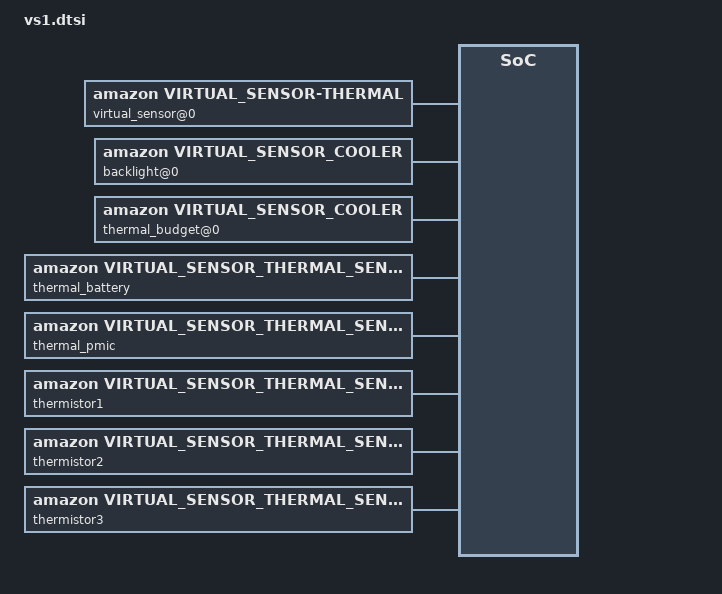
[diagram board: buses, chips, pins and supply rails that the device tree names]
/*
 * Copyright (C) 2019-2020 Amazon Technologies Inc. All rights reserved.
 *
 * This program is free software; you can redistribute it and/or modify
 * it under the terms of the GNU General Public License version 2 as
 * published by the Free Software Foundation.
 *
 * This program is distributed in the hope that it will be useful,
 * MERCHANTABILITY or FITNESS FOR A PARTICULAR PURPOSE.  See the
 * GNU General Public License for more details.
 */

/*
 * Virtual sensor
 * select_device: Decide to register which thermal_zone device
 * 0: register to thermal_zone16, 1: register to thermal_zone17
 */
virtual_sensor@0 {
	compatible = "amazon,virtual_sensor-thermal";
	dev_id = <0>;
	num_trips = <9>;
	mode = <0>;
	polling_delay = <3000>;
	governor_name = "virtual_sensor";
	num_tbps = <3>;
	temp = <44500 45000 47000 49000 50000 52000 54000 55000 56000 56000 56000 56000>;
	type = <0 0 0 0 0 0 0 0 3 3 3 3>;
	hyst = <0 0 0 0 0 0 0 3000 0 0 0 0>;
	num_cdevs = <2>;
	cdev_names = "thermal_budget0","lcd-backlight0";
};

/* Backlight Cooler */
backlight@0 {
	compatible = "amazon,virtual_sensor_cooler";
	type = "lcd-backlight0";
	state = <0>;
	max_state = <12>;
	level = <255>;
	max_level = <255>;
	thermal_cooler_id = <1>;
	levels = <255 255 255 255 255 255 175 175 175 175 175 175>;
};

/* Thermal_budget Cooler */
thermal_budget@0 {
	compatible = "amazon,virtual_sensor_cooler";
	type = "thermal_budget0";
	state = <0>;
	max_state = <12>;
	level = <4600>;
	max_level = <4600>;
	thermal_cooler_id = <2>;
	levels = <1921 1751 1669 1669 1562 1461 1358 1000 1000 1000 1000 1000>;
};

vs1_wire: vs1_wire {
	compatible = "amazon,vs1_wire", "simple-bus";
	status = "okay";
	/*Virtual sensor battery*/
	thermal_battery {
		compatible = "amazon,virtual_sensor_thermal_sensor";
		thermal_sensor,offset = <6130>;
		thermal_sensor,offset_invert = <1>;
		thermal_sensor,alpha = <1000>;
		thermal_sensor,weight = <515>;
		thermal_sensor,weight_invert = <0>;
		thermal_sensor_id = <1>;
		aux_channel_num = <0>;
		select_device = <0>;
	};

	/*Virtual sensor pmic*/
	thermal_pmic {
		compatible = "amazon,virtual_sensor_thermal_sensor";
		thermal_sensor,offset = <11200>;
		thermal_sensor,offset_invert = <1>;
		thermal_sensor,alpha = <1000>;
		thermal_sensor,weight = <262>;
		thermal_sensor,weight_invert = <0>;
		thermal_sensor_id = <3>;
		aux_channel_num = <0>;
		select_device = <0>;
	};

	/* Virtual sensor thermistor */
	thermistor1 {
		compatible = "amazon,virtual_sensor_thermal_sensor";
		thermal_sensor,offset = <33500>;
		thermal_sensor,offset_invert = <0>;
		thermal_sensor,alpha = <1000>;
		thermal_sensor,weight = <102>;
		thermal_sensor,weight_invert = <0>;
		thermal_sensor_id = <5>;
		aux_channel_num = <1>;
		select_device = <0>;
	};

	thermistor2 {
		compatible = "amazon,virtual_sensor_thermal_sensor";
		thermal_sensor,offset = <51700>;
		thermal_sensor,offset_invert = <0>;
		thermal_sensor,alpha = <1>;
		thermal_sensor,weight = <0>;
		thermal_sensor,weight_invert = <0>;
		thermal_sensor_id = <5>;
		aux_channel_num = <2>;
		select_device = <0>;
	};

	thermistor3 {
		compatible = "amazon,virtual_sensor_thermal_sensor";
		thermal_sensor,offset = <46700>;
		thermal_sensor,offset_invert = <0>;
		thermal_sensor,alpha = <147>;
		thermal_sensor,weight = <0>;
		thermal_sensor,weight_invert = <0>;
		thermal_sensor_id = <5>;
		aux_channel_num = <3>;
		select_device = <0>;
	};
};

vs1_wpc: vs1_wpc {
	compatible = "amazon,vs1_wpc", "simple-bus";
	status = "disabled";
	/*Virtual sensor battery*/
	thermal_battery {
		compatible = "amazon,virtual_sensor_thermal_sensor";
		thermal_sensor,offset = <35000>;
		thermal_sensor,offset_invert = <0>;
		thermal_sensor,alpha = <738>;
		thermal_sensor,weight = <192>;
		thermal_sensor,weight_invert = <0>;
		thermal_sensor_id = <1>;
		aux_channel_num = <0>;
		select_device = <0>;
	};

	/*Virtual sensor pmic*/
	thermal_pmic {
		compatible = "amazon,virtual_sensor_thermal_sensor";
		thermal_sensor,offset = <56500>;
		thermal_sensor,offset_invert = <0>;
		thermal_sensor,alpha = <417>;
		thermal_sensor,weight = <0>;
		thermal_sensor,weight_invert = <0>;
		thermal_sensor_id = <3>;
		aux_channel_num = <0>;
		select_device = <0>;
	};

	/* Virtual sensor thermistor */
	thermistor1 {
		compatible = "amazon,virtual_sensor_thermal_sensor";
		thermal_sensor,offset = <6420>;
		thermal_sensor,offset_invert = <0>;
		thermal_sensor,alpha = <1000>;
		thermal_sensor,weight = <943>;
		thermal_sensor,weight_invert = <0>;
		thermal_sensor_id = <5>;
		aux_channel_num = <1>;
		select_device = <0>;
	};

	thermistor2 {
		compatible = "amazon,virtual_sensor_thermal_sensor";
		thermal_sensor,offset = <53900>;
		thermal_sensor,offset_invert = <0>;
		thermal_sensor,alpha = <1>;
		thermal_sensor,weight = <0>;
		thermal_sensor,weight_invert = <0>;
		thermal_sensor_id = <5>;
		aux_channel_num = <2>;
		select_device = <0>;
	};

	thermistor3 {
		compatible = "amazon,virtual_sensor_thermal_sensor";
		thermal_sensor,offset = <61800>;
		thermal_sensor,offset_invert = <0>;
		thermal_sensor,alpha = <4>;
		thermal_sensor,weight = <276>;
		thermal_sensor,weight_invert = <1>;
		thermal_sensor_id = <5>;
		aux_channel_num = <3>;
		select_device = <0>;
	};
};
